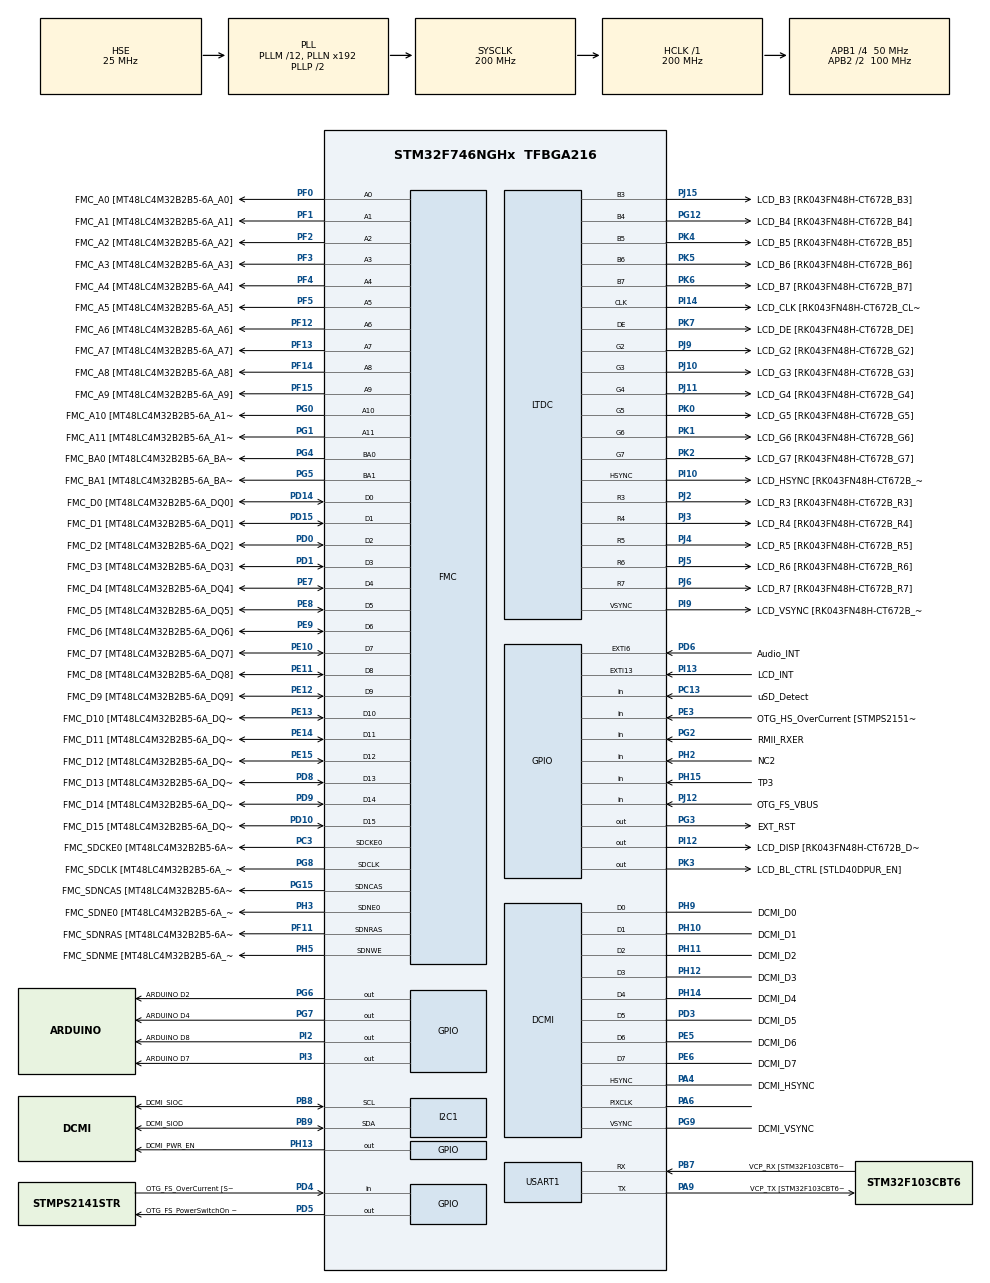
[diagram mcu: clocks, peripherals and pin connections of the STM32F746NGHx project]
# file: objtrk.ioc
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PD12.GPIO_Label=QSPI_D1 [N25Q128A13EF840E_DQ1]
FMC.SDClockPeriod2=FMC_SDRAM_CLOCK_PERIOD_2
FMC.SDClockPeriod1=FMC_SDRAM_CLOCK_PERIOD_2
SH.FMC_A0.0=FMC_A0,12b-sda1
PH15.GPIO_Label=TP3
PG8.Signal=FMC_SDCLK
PG0.Signal=FMC_A10
PI15.GPIO_Label=LCD_R0 [RK043FN48H-CT672B_R0]
PK1.Signal=LTDC_G6
SH.FMC_D5_DA5.0=FMC_D5,sd-16b-d1
PF10.GPIO_PuPd=GPIO_NOPULL
SH.FMC_D9_DA9.0=FMC_D9,sd-16b-d1
PG15.GPIO_Label=FMC_SDNCAS [MT48LC4M32B2B5-6A_CAS]
PA4.Mode=Slave_8_bits_External_Synchro
PF7.Signal=ADC3_IN5
SH.FMC_SDNWE.0=FMC_SDNWE,12b-sda1
PH9.Signal=DCMI_D0
SH.FMC_D11_DA11.0=FMC_D11,sd-16b-d1
PJ5.Mode=RGB565
RCC.APB2TimFreq_Value=200000000
PB6.Signal=QUADSPI_BK1_NCS
PC7.Signal=USART6_RX
PD0.Signal=FMC_D2_DA2
PD8.Signal=FMC_D13_DA13
PE1.Signal=FMC_NBL1
PF1.GPIO_Label=FMC_A1 [MT48LC4M32B2B5-6A_A1]
PI4.GPIO_Label=SAI2_MCLKA [WM8994ECS/R_MCLK1]
PK4.GPIO_Label=LCD_B5 [RK043FN48H-CT672B_B5]
PD1.GPIO_Label=FMC_D3 [MT48LC4M32B2B5-6A_DQ3]
DCMI.PCKPolarity=DCMI_PCKPOLARITY_RISING
PB12.GPIO_Label=ULPI_D5 [USB3320C-EZK_D5]
FMC.SelfRefreshTime1=4
PF12.GPIO_Label=FMC_A6 [MT48LC4M32B2B5-6A_A6]
LTDC.PixelFormat_L0=LTDC_PIXEL_FORMAT_RGB565
SH.S_TIM12_CH1.0=TIM12_CH1
PC4.GPIO_Label=RMII_RXD0 [LAN8742A-CZ-TR_RXD0]
PE9.Signal=FMC_D6_DA6
SH.FMC_A2.0=FMC_A2,12b-sda1
PB1.GPIO_Label=ULPI_D2 [USB3320C-EZK_D2]
PE4.GPIO_Label=LCD_B0 [RK043FN48H-CT672B_B0]
PG4.GPIO_Label=FMC_BA0 [MT48LC4M32B2B5-6A_BA0]
PA8.Signal=S_TIM1_CH1
SH.FMC_D1_DA1.0=FMC_D1,sd-16b-d1
LTDC.HSync=41
PJ14.Signal=LTDC_B2
PB9.Signal=I2C1_SDA
Mcu.Package=TFBGA216
PB1.Signal=USB_OTG_HS_ULPI_D2
PB14.GPIO_PuPd=GPIO_NOPULL
PH12.Mode=Slave_8_bits_External_Synchro
PD12.Signal=QUADSPI_BK1_IO1
PH11.Mode=Slave_8_bits_External_Synchro
PB9.GPIO_PuPd=GPIO_NOPULL
PA10.Signal=USB_OTG_FS_ID
PE12.GPIO_Label=FMC_D9 [MT48LC4M32B2B5-6A_DQ9]
FMC.WriteRecoveryTime1=3
RCC.APB2CLKDivider=RCC_HCLK_DIV2
LTDC.VSync=10
RCC.APB1TimFreq_Value=100000000
PC14/OSC32_IN.GPIO_Label=RCC_OSC32_IN
FMC.RowCycleDelay2=7
FMC.RowCycleDelay1=7
PF9.GPIO_PuPd=GPIO_NOPULL
PA4.GPIO_Label=DCMI_HSYNC
PA8.GPIO_Speed=GPIO_SPEED_FREQ_LOW
PD15.Signal=FMC_D1_DA1
PJ1.GPIO_Label=LCD_R2 [RK043FN48H-CT672B_R2]
PG12.Signal=LTDC_B4
SH.FMC_A4.0=FMC_A4,12b-sda1
PK4.Signal=LTDC_B5
PH13.Signal=GPIO_Output
PI13.GPIO_ModeDefaultEXTI=GPIO_MODE_EVT_RISING
PG5.Signal=FMC_A15_BA1
PC13.Signal=GPIO_Input
SH.FMC_D10_DA10.0=FMC_D10,sd-16b-d1
PD3.Signal=DCMI_D5
PI10.Mode=RGB565
PG9.Mode=Slave_8_bits_External_Synchro
PC2.Signal=USB_OTG_HS_ULPI_DIR
PI12.Signal=GPIO_Output
PJ11.Signal=LTDC_G4
PF8.GPIO_Label=ARDUINO A3
LTDC.ImageWidth_L0=480
PD10.Signal=FMC_D15_DA15
PJ6.Mode=RGB565
PB8.GPIO_Label=DCMI_SIOC
PJ8.GPIO_Label=LCD_G1 [RK043FN48H-CT672B_G1]
PJ3.Signal=LTDC_R4
PI8.GPIO_Label=NC1 [TP2]
PA8.GPIO_Label=ARDUINO PWM/D10
PE8.GPIO_Label=FMC_D5 [MT48LC4M32B2B5-6A_DQ5]
PH9.Mode=Slave_8_bits_External_Synchro
PH11.GPIO_Label=DCMI_D2
PJ11.GPIO_Label=LCD_G4 [RK043FN48H-CT672B_G4]
PB14.Signal=SPI2_MISO
PA5.Signal=USB_OTG_HS_ULPI_CK
PF10.GPIO_Mode=GPIO_MODE_ANALOG
PJ4.GPIO_Label=LCD_R5 [RK043FN48H-CT672B_R5]
PE1.GPIO_Label=FMC_NBL1 [MT48LC4M32B2B5-6A_DQM1]
PK7.GPIO_Label=LCD_DE [RK043FN48H-CT672B_DE]
PI7.Signal=SAI2_FS_A
FMC.ReadBurst1=FMC_SDRAM_RBURST_ENABLE
SH.FMC_A6.0=FMC_A6,12b-sda1
FMC.ReadBurst2=FMC_SDRAM_RBURST_ENABLE
PE14.Signal=FMC_D11_DA11
PE6.Mode=Slave_8_bits_External_Synchro
PB4.GPIO_Label=ARDUINO PWM/D3
PB15.GPIO_Label=ARDUINO MOSI/PWM/D11
PG7.GPIO_Label=ARDUINO D4
PI2.Signal=GPIO_Output
PF4.GPIO_Label=FMC_A4 [MT48LC4M32B2B5-6A_A4]
PA1.GPIO_Label=RMII_REF_CLK [LAN8742A-CZ-TR_REFCLK0]
PF13.Signal=FMC_A7
PA0/WKUP.GPIO_PuPd=GPIO_NOPULL
PJ15.GPIO_Label=LCD_B3 [RK043FN48H-CT672B_B3]
PC7.GPIO_Label=ARDUINO RX/D0
PJ15.Mode=RGB565
PA5.GPIO_Label=ULPI_CLK [USB3320C-EZK_CLKOUT]
PK4.Mode=RGB565
PC12.GPIO_Label=SDMMC_CK
PE5.GPIO_Label=DCMI_D6
PJ8.Signal=LTDC_G1
PJ0.GPIO_Label=LCD_R1 [RK043FN48H-CT672B_R1]
ProjectManager.HeapSize=0x200
PH6.Signal=S_TIM12_CH1
NVIC.PriorityGroup=NVIC_PRIORITYGROUP_4
PF0.GPIO_Label=FMC_A0 [MT48LC4M32B2B5-6A_A0]
PI1.GPIO_Mode=GPIO_MODE_AF_PP
PE3.Signal=GPIO_Input
PJ4.Mode=RGB565
PC15/OSC32_OUT.Signal=RCC_OSC32_OUT
Dma.DCMI.0.PeriphInc=DMA_PINC_DISABLE
PF4.Signal=FMC_A4
PD2.Signal=SDMMC1_CMD
PI1.GPIO_Label=ARDUINO SCK/D13
Mcu.Family=STM32F7
LTDC.BlendingFactor1_L0=LTDC_BLENDING_FACTOR1_PAxCA
PA6.Mode=Slave_8_bits_External_Synchro
PK3.Signal=GPIO_Output
SH.FMC_A8.0=FMC_A8,12b-sda1
PC15/OSC32_OUT.GPIO_Label=RCC_OSC32_OUT
PH14.Signal=DCMI_D4
PH10.Signal=DCMI_D1
SH.FMC_D14_DA14.0=FMC_D14,sd-16b-d1
PG2.Signal=GPIO_Input
PE11.GPIO_Label=FMC_D8 [MT48LC4M32B2B5-6A_DQ8]
PD0.GPIO_Label=FMC_D2 [MT48LC4M32B2B5-6A_DQ2]
PC14/OSC32_IN.Mode=LSE-External-Oscillator
SH.FMC_A14_BA0.0=FMC_BA0,FourSdramBanks1
SH.FMC_A11.0=FMC_A11,12b-sda1
PB13.GPIO_Label=ULPI_D6 [USB3320C-EZK_D6]
PG5.GPIO_Label=FMC_BA1 [MT48LC4M32B2B5-6A_BA1]
PB15.Signal=SPI2_MOSI
PG15.Signal=FMC_SDNCAS
PG11.Signal=ETH_TX_EN
PJ5.GPIO_Label=LCD_R6 [RK043FN48H-CT672B_R6]
PJ14.GPIO_Label=LCD_B2 [RK043FN48H-CT672B_B2]
Dma.DCMI.0.FIFOMode=DMA_FIFOMODE_ENABLE
PD13.Signal=QUADSPI_BK1_IO3
Dma.DCMI.0.FIFOThreshold=DMA_FIFO_THRESHOLD_FULL
PA15.GPIO_Label=ARDUINO PWM/D9
Dma.DCMI.0.MemInc=DMA_MINC_ENABLE
PJ2.Signal=LTDC_R3
PH10.Mode=Slave_8_bits_External_Synchro
SH.FMC_NBL1.0=FMC_NBL1
LTDC.WindowX1_L0=480
PI9.Mode=RGB565
PK2.Mode=RGB565
PA15.GPIO_ModeDefaultPP=GPIO_MODE_AF_PP
PA9.GPIO_Mode=GPIO_MODE_AF_PP
RCC.HSE_VALUE=25000000
FMC.ExitSelfRefreshDelay1=7
PF7.GPIO_Mode=GPIO_MODE_ANALOG
PI14.Mode=RGB565
PF8.GPIO_PuPd=GPIO_NOPULL
PH7.GPIO_Label=LCD_SCL [RK043FN48H-CT672B_SCL]
PJ7.GPIO_Label=LCD_G0 [RK043FN48H-CT672B_G0]
PF11.Signal=FMC_SDNRAS
PC11.GPIO_Label=SDMMC_D3
PJ12.GPIO_Label=OTG_FS_VBUS
PB7.Signal=USART1_RX
Dma.DCMI.0.PeriphBurst=DMA_PBURST_SINGLE
SH.S_TIM3_CH1.0=TIM3_CH1
PB7.GPIO_Label=VCP_RX [STM32F103CBT6_PA2]
PD13.GPIO_Label=QSPI_D3 [N25Q128A13EF840E_DQ3]
PA6.Signal=DCMI_PIXCLK
Dma.DCMI.0.Direction=DMA_PERIPH_TO_MEMORY
PB15.GPIO_PuPd=GPIO_NOPULL
PD5.GPIO_Label=OTG_FS_PowerSwitchOn [STMPS2141STR_EN]
PA15.Signal=S_TIM2_CH1_ETR
PF8.Signal=ADC3_IN6
PG0.GPIO_Label=FMC_A10 [MT48LC4M32B2B5-6A_A10]
PI0.GPIO_Label=ARDUINO PWM/CS/D5
PA0/WKUP.GPIO_Mode=GPIO_MODE_ANALOG
PB5.GPIO_Label=ULPI_D7 [USB3320C-EZK_D7]
PG11.GPIO_Label=RMII_TX_EN [LAN8742A-CZ-TR_TXEN]
PD3.GPIO_Label=DCMI_D5
PC5.Signal=ETH_RXD1
PE7.Signal=FMC_D4_DA4
PD6.Signal=GPXTI6
Dma.Request0=DCMI
PF3.GPIO_Label=FMC_A3 [MT48LC4M32B2B5-6A_A3]
PE2.GPIO_Label=QSPI_D2 [N25Q128A13EF840E_DQ2]
PB4.Signal=S_TIM3_CH1
PG2.GPIO_Label=RMII_RXER
PA3.Signal=USB_OTG_HS_ULPI_D0
PK1.Mode=RGB565
PK6.Signal=LTDC_B7
NVIC.LTDC_IRQn=true\:0\:0\:false\:false\:true\:true\:true
PD15.GPIO_Label=FMC_D1 [MT48LC4M32B2B5-6A_DQ1]
LTDC.WindowY1_L0=272
PG7.Signal=GPIO_Output
PH12.GPIO_Label=DCMI_D3
PC11.Signal=SDMMC1_D3
PI14.Signal=LTDC_CLK
PC8.Signal=SDMMC1_D0
PE14.GPIO_Label=FMC_D11 [MT48LC4M32B2B5-6A_DQ11]
PD9.Signal=FMC_D14_DA14
PA9.GPIO_PuPd=GPIO_NOPULL
PA12.GPIO_Label=OTG_FS_P
PD8.GPIO_Label=FMC_D13 [MT48LC4M32B2B5-6A_DQ13]
PG8.GPIO_Label=FMC_SDCLK [MT48LC4M32B2B5-6A_CLK]
USART1.VirtualMode-Asynchronous=VM_ASYNC
PA13.Signal=SYS_JTMS-SWDIO
PA9.Mode=Asynchronous
SH.S_TIM1_CH1.0=TIM1_CH1
PF6.Signal=ADC3_IN4
PB10.GPIO_Label=ULPI_D3 [USB3320C-EZK_D3]
SH.FMC_D13_DA13.0=FMC_D13,sd-16b-d1
PH8.Signal=I2C3_SDA
PB9.Mode=I2C
Dma.DCMI.0.Instance=DMA2_Stream1
Dma.DCMI.0.Mode=DMA_CIRCULAR
RCC.USBFreq_Value=200000000
PF9.GPIO_Label=ARDUINO A2
PD10.GPIO_Label=FMC_D15 [MT48LC4M32B2B5-6A_DQ15]
PA1.Signal=ETH_REF_CLK
PK5.Mode=RGB565
board=STM32F746G-DISCO
PG12.Mode=RGB565
RCC.VCOOutputFreq_Value=400000000
PI9.Signal=LTDC_VSYNC
PH4.GPIO_Label=ULPI_NXT [USB3320C-EZK_NXT]
PI13.GPIO_Label=LCD_INT
PI4.Signal=SAI2_MCLK_A
PE5.Mode=Slave_8_bits_External_Synchro
PC1.GPIO_Label=RMII_MDC [LAN8742A-CZ-TR_MDC]
SH.FMC_D12_DA12.0=FMC_D12,sd-16b-d1
PF15.GPIO_Label=FMC_A9 [MT48LC4M32B2B5-6A_A9]
PI1.GPIO_Speed=GPIO_SPEED_FREQ_LOW
PF1.Signal=FMC_A1
PF8.GPIO_Mode=GPIO_MODE_ANALOG
PJ0.Signal=LTDC_R1
PE0.Signal=FMC_NBL0
PE7.GPIO_Label=FMC_D4 [MT48LC4M32B2B5-6A_DQ4]
PE12.Signal=FMC_D9_DA9
RCC.SYSCLKFreq_VALUE=200000000
PJ5.Signal=LTDC_R6
PA15.GPIO_Speed=GPIO_SPEED_FREQ_LOW
RCC.HSI_VALUE=16000000
PA8.GPIO_PuPd=GPIO_NOPULL
PH0/OSC_IN.GPIO_Label=OSC_25M [NZ2520SB-25.00M_OUT]
PF9.GPIO_Mode=GPIO_MODE_ANALOG
PI3.GPIO_Label=ARDUINO D7
PH3.Signal=FMC_SDNE0
RCC.PLLM=12
PA9.GPIO_Speed=GPIO_SPEED_FREQ_LOW
PB8.GPIO_Speed=GPIO_SPEED_FREQ_LOW
PJ2.GPIO_Label=LCD_R3 [RK043FN48H-CT672B_R3]
LTDC.ImageHeight_L0=272
PB14.GPIO_Mode=GPIO_MODE_AF_PP
PB12.Signal=USB_OTG_HS_ULPI_D5
PJ13.Signal=LTDC_B1
PK1.GPIO_Label=LCD_G6 [RK043FN48H-CT672B_G6]
PA3.GPIO_Label=ULPI_D0 [USB3320C-EZK_D0]
PI12.PinState=GPIO_PIN_SET
SH.FMC_D7_DA7.0=FMC_D7,sd-16b-d1
PK5.Signal=LTDC_B6
PB15.GPIO_Mode=GPIO_MODE_AF_PP
PJ9.Mode=RGB565
PH12.Signal=DCMI_D3
FMC.RCDDelay1=2
PK0.Mode=RGB565
PG4.Signal=FMC_A14_BA0
PC12.Signal=SDMMC1_CK
PB14.GPIO_Label=ARDUINO MISO/D12
PA14.GPIO_Label=SWCLK
PG6.GPIO_Label=ARDUINO D2
PH6.GPIO_Label=ARDUINO PWM/D6
FMC.LoadToActiveDelay1=2
PK6.GPIO_Label=LCD_B7 [RK043FN48H-CT672B_B7]
PC6.GPIO_Label=ARDUINO TX/D1
PI6.GPIO_Label=SAI2_SDA [WM8994ECS/R_DACDAT1]
PB6.GPIO_Label=QSPI_NCS [N25Q128A13EF840E_S]
PJ6.GPIO_Label=LCD_R7 [RK043FN48H-CT672B_R7]
Dma.DCMI.0.MemBurst=DMA_MBURST_SINGLE
PB13.Signal=USB_OTG_HS_ULPI_D6
PD6.GPIO_Label=Audio_INT
PG13.Signal=ETH_TXD0
PE6.GPIO_Label=DCMI_D7
PF6.GPIO_Label=ARDUINO A5
RCC.SYSCLKSource=RCC_SYSCLKSOURCE_PLLCLK
PJ10.Signal=LTDC_G3
SH.FMC_A15_BA1.0=FMC_BA1,FourSdramBanks1
Dma.DCMI.0.MemDataAlignment=DMA_MDATAALIGN_WORD
PB7.GPIO_Mode=GPIO_MODE_AF_PP
PJ13.GPIO_Label=LCD_B1 [RK043FN48H-CT672B_B1]
PI0.GPIO_PuPd=GPIO_NOPULL
PH5.Signal=FMC_SDNWE
Dma.DCMI.0.PeriphDataAlignment=DMA_PDATAALIGN_WORD
PD4.Signal=GPIO_Input
PH1/OSC_OUT.Signal=RCC_OSC_OUT
PC3.Signal=FMC_SDCKE0
PE5.Signal=DCMI_D6
PF10.GPIO_Label=ARDUINO A1
PH10.GPIO_Label=DCMI_D1
PB2.Signal=QUADSPI_CLK
PK7.Mode=RGB565
PJ2.Mode=RGB565
PI6.Signal=SAI2_SD_A
PI3.Signal=GPIO_Output
PE2.Signal=QUADSPI_BK1_IO2
PF3.Signal=FMC_A3
PD3.Mode=Slave_8_bits_External_Synchro
PE10.Signal=FMC_D7_DA7
PD6.GPIO_ModeDefaultEXTI=GPIO_MODE_EVT_RISING
PJ4.Signal=LTDC_R5
SH.FMC_A1.0=FMC_A1,12b-sda1
PH2.Signal=GPIO_Input
SH.FMC_SDCLK.0=FMC_SDCLK,12b-sda1
PF14.Signal=FMC_A8
VP_DMA2D_VS_DMA2D.Mode=DMA2D_Activate
PF6.GPIO_Mode=GPIO_MODE_ANALOG
PE10.GPIO_Label=FMC_D7 [MT48LC4M32B2B5-6A_DQ7]
SH.FMC_D3_DA3.0=FMC_D3,sd-16b-d1
PI10.GPIO_Label=LCD_HSYNC [RK043FN48H-CT672B_HSYNC]
PB7.GPIO_PuPd=GPIO_NOPULL
PK3.PinState=GPIO_PIN_SET
PH15.Signal=GPIO_Input
PD9.GPIO_Label=FMC_D14 [MT48LC4M32B2B5-6A_DQ14]
PG9.Signal=DCMI_VSYNC
PA9.GPIO_Label=VCP_TX [STM32F103CBT6_PA3]
PB8.GPIO_PuPd=GPIO_NOPULL
PC6.Signal=USART6_TX
PB11.GPIO_Label=ULPI_D4 [USB3320C-EZK_D4]
PD7.Signal=SPDIFRX_IN0
PD1.Signal=FMC_D3_DA3
PA11.GPIO_Label=OTG_FS_N
PF14.GPIO_Label=FMC_A8 [MT48LC4M32B2B5-6A_A8]
NVIC.DMA2_Stream1_IRQn=true\:0\:0\:false\:false\:true\:false\:true
PC0.Signal=USB_OTG_HS_ULPI_STP
RCC.APB1CLKDivider=RCC_HCLK_DIV4
PF13.GPIO_Label=FMC_A7 [MT48LC4M32B2B5-6A_A7]
PG13.GPIO_Label=RMII_TXD0 [LAN8742A-CZ-TR_TXD0]
PG10.Signal=SAI2_SD_B
SH.FMC_A3.0=FMC_A3,12b-sda1
PJ7.Signal=LTDC_G0
FMC.CASLatency1=FMC_SDRAM_CAS_LATENCY_2
PI0.GPIO_Speed=GPIO_SPEED_FREQ_LOW
PB14.GPIO_Speed=GPIO_SPEED_FREQ_LOW
SH.FMC_D15_DA15.0=FMC_D15,sd-16b-d1
PA9.Signal=USART1_TX
I2C1.Timing=0x00C0EAFF
PB4.GPIO_PuPd=GPIO_NOPULL
PE9.GPIO_Label=FMC_D6 [MT48LC4M32B2B5-6A_DQ6]
PB10.Signal=USB_OTG_HS_ULPI_D3
PJ15.Signal=LTDC_B3
PH9.GPIO_Label=DCMI_D0
PI9.GPIO_Label=LCD_VSYNC [RK043FN48H-CT672B_VSYNC]
PA8.GPIO_ModeDefaultPP=GPIO_MODE_AF_PP
PH14.Mode=Slave_8_bits_External_Synchro
PE15.Signal=FMC_D12_DA12
PE8.Signal=FMC_D5_DA5
PI1.Signal=SPI2_SCK
PA0/WKUP.GPIO_Label=ARDUINO A0
PG14.GPIO_Label=RMII_TXD1 [LAN8742A-CZ-TR_TXD1]
SH.FMC_SDNCAS.0=FMC_SDNCAS,12b-sda1
PF7.GPIO_PuPd=GPIO_NOPULL
PH14.GPIO_Label=DCMI_D4
PA4.Signal=DCMI_HSYNC
PB5.Signal=USB_OTG_HS_ULPI_D7
PE13.GPIO_Label=FMC_D10 [MT48LC4M32B2B5-6A_DQ10]
PD11.Signal=QUADSPI_BK1_IO0
SH.FMC_A5.0=FMC_A5,12b-sda1
LTDC.Alpha_L0=255
PA11.Signal=USB_OTG_FS_DM
SH.S_TIM2_CH1_ETR.0=TIM2_CH1
PK3.GPIO_Label=LCD_BL_CTRL [STLD40DPUR_EN]
PF9.Signal=ADC3_IN7
PJ10.Mode=RGB565
PB8.Mode=I2C
PF6.GPIO_PuPd=GPIO_NOPULL
PC3.GPIO_Label=FMC_SDCKE0 [MT48LC4M32B2B5-6A_CKE]
PG3.GPIO_Label=EXT_RST
PB0.Signal=USB_OTG_HS_ULPI_D1
PC1.Signal=ETH_MDC
PG10.GPIO_Label=SAI2_SDB [WM8994ECS/R_ADCDAT1]
PD2.GPIO_Label=SDMMC_D0
PH2.GPIO_Label=NC2
Dma.DCMI.0.Priority=DMA_PRIORITY_VERY_HIGH
PC3.Mode=SdramChipSelect1_1
PK7.Signal=LTDC_DE
RCC.CortexFreq_Value=200000000
PG6.Signal=GPIO_Output
LTDC.HBP=13
PC10.Signal=SDMMC1_D2
SH.FMC_NBL0.0=FMC_NBL0
PC0.GPIO_Label=ULPI_STP [USB3320C-EZK_STP]
SH.FMC_D6_DA6.0=FMC_D6,sd-16b-d1
PA0/WKUP.Signal=ADCx_IN0
PB0.GPIO_Label=ULPI_D1 [USB3320C-EZK_D1]
PH5.GPIO_Label=FMC_SDNME [MT48LC4M32B2B5-6A_WE]
PI5.GPIO_Label=SAI2_SCKA [WM8994ECS/R_BCLK1]
PC13.GPIO_Label=uSD_Detect
PK5.GPIO_Label=LCD_B6 [RK043FN48H-CT672B_B6]
PB11.Signal=USB_OTG_HS_ULPI_D4
PI14.GPIO_Label=LCD_CLK [RK043FN48H-CT672B_CLK]
ProjectManager.StackSize=0x400
PH3.Mode=SdramChipSelect1_1
PJ6.Signal=LTDC_R7
SH.FMC_A7.0=FMC_A7,12b-sda1
PA12.Signal=USB_OTG_FS_DP
PH0/OSC_IN.Mode=HSE-External-Oscillator
PD11.GPIO_Label=QSPI_D0 [N25Q128A13EF840E_DQ0]
RCC.HCLKFreq_Value=200000000
DCMI.VSPolarity=DCMI_VSPOLARITY_HIGH
PF11.GPIO_Label=FMC_SDNRAS [MT48LC4M32B2B5-6A_RAS]
PF12.Signal=FMC_A6
PI13.Signal=GPXTI13
SH.FMC_A10.0=FMC_A10,12b-sda1
RCC.AHBFreq_Value=200000000
SH.FMC_D8_DA8.0=FMC_D8,sd-16b-d1
FMC.RPDelay2=2
FMC.RPDelay1=2
PI8.Signal=RTC_TS
SH.FMC_D2_DA2.0=FMC_D2,sd-16b-d1
PE13.Signal=FMC_D10_DA10
PF7.GPIO_Label=ARDUINO A4
PI1.GPIO_PuPd=GPIO_NOPULL
PI5.Signal=SAI2_SCK_A
PK6.Mode=RGB565
PI0.Signal=S_TIM5_CH4
PA10.GPIO_Label=OTG_FS_ID
LTDC.HFP=32
LTDC.BlendingFactor2_L0=LTDC_BLENDING_FACTOR2_PAxCA
SH.ADCx_IN0.0=ADC3_IN0
SH.FMC_SDNRAS.0=FMC_SDNRAS,12b-sda1
DMA2D.ColorMode=DMA2D_OUTPUT_RGB565
LTDC.ActiveW=480
PE4.Signal=LTDC_B0
PH1/OSC_OUT.Mode=HSE-External-Oscillator
PD7.GPIO_Label=SPDIF_RX0 [74LVC1G04SE_4]
PJ9.Signal=LTDC_G2
SH.FMC_D0_DA0.0=FMC_D0,sd-16b-d1
PJ12.Signal=GPIO_Input
PC14/OSC32_IN.Signal=RCC_OSC32_IN
PK0.GPIO_Label=LCD_G5 [RK043FN48H-CT672B_G5]
PA2.GPIO_Label=RMII_MDIO [LAN8742A-CZ-TR_MDIO]
PF5.GPIO_Label=FMC_A5 [MT48LC4M32B2B5-6A_A5]
SH.FMC_A9.0=FMC_A9,12b-sda1
PJ1.Signal=LTDC_R2
SH.FMC_D4_DA4.0=FMC_D4,sd-16b-d1
PI12.GPIO_Label=LCD_DISP [RK043FN48H-CT672B_DISP] 
PE0.GPIO_Label=FMC_NBL0 [MT48LC4M32B2B5-6A_DQM0]
RCC.PLLSAIN=50
PH3.GPIO_Label=FMC_SDNE0 [MT48LC4M32B2B5-6A_CS]
PF5.Signal=FMC_A5
PH7.Signal=I2C3_SCL
PB9.GPIO_Speed=GPIO_SPEED_FREQ_LOW
PJ3.GPIO_Label=LCD_R4 [RK043FN48H-CT672B_R4]
PK2.GPIO_Label=LCD_G7 [RK043FN48H-CT672B_G7]
PF0.Signal=FMC_A0
PI2.GPIO_Label=ARDUINO D8
PC2.GPIO_Label=ULPI_DIR [USB3320C-EZK_DIR]
PB7.GPIO_Speed=GPIO_SPEED_FREQ_LOW
PB3.GPIO_Label=SWO
RCC.PLLSourceVirtual=RCC_PLLSOURCE_HSE
PK2.Signal=LTDC_G7
LTDC.FBStartAdress_L0=0xC0000000
PB9.GPIO_Label=DCMI_SIOD
PC10.GPIO_Label=SDMMC_D2
PH11.Signal=DCMI_D2
PG3.Signal=GPIO_Output
PG1.Signal=FMC_A11
PC4.Signal=ETH_RXD0
PI0.GPIO_ModeDefaultPP=GPIO_MODE_AF_PP
PI10.Signal=LTDC_HSYNC
PD5.Signal=GPIO_Output
PJ11.Mode=RGB565
PH13.GPIO_Label=DCMI_PWR_EN
PH8.GPIO_Label=LCD_SDA [RK043FN48H-CT672B_SDA]
PE15.GPIO_Label=FMC_D12 [MT48LC4M32B2B5-6A_DQ12]
PH4.Signal=USB_OTG_HS_ULPI_NXT
ProjectManager.TargetToolchain=STM32CubeIDE
LTDC.ActiveH=272
PJ9.GPIO_Label=LCD_G2 [RK043FN48H-CT672B_G2]
PF2.Signal=FMC_A2
PE11.Signal=FMC_D8_DA8
PK0.Signal=LTDC_G5
PG9.GPIO_Label=DCMI_VSYNC
PG14.Signal=ETH_TXD1
PB4.GPIO_ModeDefaultPP=GPIO_MODE_AF_PP
PJ10.GPIO_Label=LCD_G3 [RK043FN48H-CT672B_G3]
PG1.GPIO_Label=FMC_A11 [MT48LC4M32B2B5-6A_A11]
PB9.GPIO_Mode=GPIO_MODE_AF_OD
PJ3.Mode=RGB565
PH0/OSC_IN.Signal=RCC_OSC_IN
PB4.GPIO_Speed=GPIO_SPEED_FREQ_LOW
RCC.APB2Freq_Value=100000000
LTDC.Layers=0
PD4.GPIO_Label=OTG_FS_OverCurrent [STMPS2141STR_Fault]
PF10.Signal=ADC3_IN8
PB15.GPIO_Speed=GPIO_SPEED_FREQ_LOW
PI7.GPIO_Label=SAI2_FSA [WM8994ECS/R_LRCLK1]
SH.S_TIM5_CH4.0=TIM5_CH4
PF15.Signal=FMC_A9
PD14.GPIO_Label=FMC_D0 [MT48LC4M32B2B5-6A_DQ0]
PD5.PinState=GPIO_PIN_SET
PE6.Signal=DCMI_D7
Mcu.Name=STM32F746NGHx
PA13.GPIO_Label=SWDIO
PA2.Signal=ETH_MDIO
PD14.Signal=FMC_D0_DA0
PB3.Signal=SYS_JTDO-SWO
PA7.GPIO_Label=RMII_CRS_DV [LAN8742A-CZ-TR_CRS_DV]
PC5.GPIO_Label=RMII_RXD1 [LAN8742A-CZ-TR_RXD1]
PC15/OSC32_OUT.Mode=LSE-External-Oscillator
PB7.Mode=Asynchronous
PA14.Signal=SYS_JTCK-SWCLK
PG12.GPIO_Label=LCD_B4 [RK043FN48H-CT672B_B4]
PA15.GPIO_PuPd=GPIO_NOPULL
PI15.Signal=LTDC_R0
PB8.Signal=I2C1_SCL
PE3.GPIO_Label=OTG_HS_OverCurrent [STMPS2151STR_FAULT]
PC9.Signal=SDMMC1_D1
NVIC.DCMI_IRQn=true\:0\:0\:false\:false\:true\:true\:true
PB8.GPIO_Mode=GPIO_MODE_AF_OD
RCC.APB1Freq_Value=50000000
DMA2D.Mode=DMA2D_M2M
PA7.Signal=ETH_CRS_DV
PF2.GPIO_Label=FMC_A2 [MT48LC4M32B2B5-6A_A2]

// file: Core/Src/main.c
/* USER CODE BEGIN Header */
/**
  ******************************************************************************
  * @file           : main.c
  * @brief          : Main program body
  ******************************************************************************
  * @attention
  *
  * <h2><center>&copy; Copyright (c) 2021 STMicroelectronics.
  * All rights reserved.</center></h2>
  *
  * This software component is licensed by ST under BSD 3-Clause license,
  * the "License"; You may not use this file except in compliance with the
  * License. You may obtain a copy of the License at:
  *                        opensource.org/licenses/BSD-3-Clause
  *
  ******************************************************************************
  */
/* USER CODE END Header */
#include "main.h"

DCMI_HandleTypeDef hdcmi;
DMA_HandleTypeDef hdma_dcmi;

DMA2D_HandleTypeDef hdma2d;

I2C_HandleTypeDef hi2c1;

LTDC_HandleTypeDef hltdc;

UART_HandleTypeDef huart1;

SDRAM_HandleTypeDef hsdram1;

void SystemClock_Config(void);
static void MX_GPIO_Init(void);
static void MX_DMA_Init(void);
static void MX_USART1_UART_Init(void);
static void MX_FMC_Init(void);
static void MX_LTDC_Init(void);
static void MX_DMA2D_Init(void);
static void MX_DCMI_Init(void);
static void MX_I2C1_Init(void);

/* USER CODE BEGIN 0 */
int __io_putchar(int ch) {
	if ( HAL_UART_Transmit(&huart1, (uint8_t*)&ch, 1, 1000) == HAL_OK )
		return ch;
	else
		return 0;
}

int dma2d_fps = 0;
int dcmi_fps = 0;

#define SCREEN_W (480)
#define SCREEN_H (272)
#define VRAM_SIZE (2 * SCREEN_W * SCREEN_H)

#define CAPTURE_W (240)
#define CAPTURE_H (240)
#define CAPTURE_SIZE (2 * CAPTURE_W * CAPTURE_H)

uint16_t buf[CAPTURE_W * CAPTURE_H];
#define CAPTURE_MEM ((uint32_t)((uint16_t *)buf))
#define CAPTURE_MEM0 (SDRAM_BANK_ADDR + VRAM_SIZE)
#define CAPTURE_MEM1 (SDRAM_BANK_ADDR + VRAM_SIZE + 2 * CAPTURE_SIZE)

bool dcmi_sw = false;
uint32_t buffaddr[2] = { CAPTURE_MEM0, CAPTURE_MEM1 };

void HAL_DCMI_FrameEventCallback(DCMI_HandleTypeDef *hdcmi) {

	dcmi_fps++;

	HAL_DCMI_Stop(hdcmi);

	HAL_DMA2D_Start_IT(
			&hdma2d,
			buffaddr[dcmi_sw],
			SDRAM_BANK_ADDR + ((SCREEN_W - CAPTURE_W) / 2 + ((SCREEN_H - CAPTURE_H) /  2) * SCREEN_W) * 2,
			CAPTURE_W,
			CAPTURE_H
	);

	dcmi_sw = !dcmi_sw;

	HAL_DCMI_Start_DMA(hdcmi, DCMI_MODE_SNAPSHOT, buffaddr[dcmi_sw], CAPTURE_SIZE / 4);

}

void DMA2D_XferCpltCallback(DMA2D_HandleTypeDef *hdma2d) {

	dma2d_fps++;

}

void DMA2D_XferErrorCallback(DMA2D_HandleTypeDef *hdma2d) {

	printf("DMA2D XferError\r\n");

}
/* USER CODE END 0 */

int main(void)
{

  /* MCU Configuration--------------------------------------------------------*/

  /* Reset of all peripherals, Initializes the Flash interface and the Systick. */
  HAL_Init();

  /* Configure the system clock */
  SystemClock_Config();

  /* Initialize all configured peripherals */
  MX_GPIO_Init();
  MX_DMA_Init();
  MX_USART1_UART_Init();
  MX_FMC_Init();
  MX_LTDC_Init();
  MX_DMA2D_Init();
  MX_DCMI_Init();
  MX_I2C1_Init();
  /* USER CODE BEGIN 2 */

  SDRAM_Initialization_sequence();
  printf("SDRAM INIT SEQ DONE\r\n");

  CAMERA_Initialization_sequence();
  printf("CAMERA INIT SEQ DONE\r\n");

  hdma2d.Init.Mode = DMA2D_R2M;
  HAL_DMA2D_Init(&hdma2d);
  HAL_DMA2D_Start(&hdma2d, 0, 0xC0000000, SCREEN_W, SCREEN_H);
  HAL_DMA2D_PollForTransfer(&hdma2d, 10);

  hdma2d.Init.Mode = DMA2D_M2M;
  hdma2d.Init.OutputOffset = SCREEN_W - CAPTURE_W; // number of pixels on each line that should be ignored
  hdma2d.XferCpltCallback = DMA2D_XferCpltCallback;
  HAL_DMA2D_Init(&hdma2d);

  /* For 240x240 resolution, the OV9655 sensor is set to QVGA resolution
   * as OV9655 doesn't supports 240x240  resolution,
   * then DCMI is configured to output a 240x240 cropped window
   *
   * CWSIZER; DCMI crop window size,
   * CWSTRTR; DCMI crop window start,
   *
   * hdcmi->Instance->CWSIZER = (XSize | (YSize << DCMI_CWSIZE_VLINE_Pos));
   * hdcmi->Instance->CWSTRTR = (X0 | (Y0 << DCMI_CWSTRT_VST_Pos));
   */
  HAL_DCMI_ConfigCrop(
		  &hdcmi,
		  40,            /* X0 DCMI window X offset   : Crop in the middle of the VGA picture */
		  0,             /* Y0 DCMI window Y offset   : Same height (same number of lines: no need to crop vertically) */
		  (240 * 2) - 1, /* XSIZE DCMI Pixel per line : 2 pixels clock needed to capture one pixel */
		  (240 * 1) - 1  /* YSIZE DCMI Line number    : All 240 lines are captured */
  );
  HAL_DCMI_EnableCrop(&hdcmi);

  HAL_DMA2D_ConfigDeadTime(&hdma2d, 2);
  HAL_DMA2D_EnableDeadTime(&hdma2d);

  HAL_DCMI_Start_DMA(&hdcmi, DCMI_MODE_SNAPSHOT, buffaddr[dcmi_sw], CAPTURE_SIZE / 4);

  /* USER CODE END 2 */

  /* Infinite loop */
  /* USER CODE BEGIN WHILE */
  while (1)
  {
	printf("[FPS] DMA2D[%i]: %i | DCMI[%i]: %i\r\n", hdma2d.State, dma2d_fps, hdcmi.State, dcmi_fps);
	dma2d_fps = 0; dcmi_fps = 0;
	HAL_Delay(1000);

	// you gonk watchdog on dma transfers and restart dcmi if no update
	HAL_DCMI_Stop(&hdcmi);
	HAL_DCMI_Start_DMA(&hdcmi, DCMI_MODE_SNAPSHOT, buffaddr[dcmi_sw], CAPTURE_SIZE / 4);
    /* USER CODE END WHILE */

  }
}

void SystemClock_Config(void)
{
  RCC_OscInitTypeDef RCC_OscInitStruct = {0};
  RCC_ClkInitTypeDef RCC_ClkInitStruct = {0};
  RCC_PeriphCLKInitTypeDef PeriphClkInitStruct = {0};

  /** Configure LSE Drive Capability
  */
  HAL_PWR_EnableBkUpAccess();
  /** Configure the main internal regulator output voltage
  */
  __HAL_RCC_PWR_CLK_ENABLE();
  __HAL_PWR_VOLTAGESCALING_CONFIG(PWR_REGULATOR_VOLTAGE_SCALE1);
  /** Initializes the RCC Oscillators according to the specified parameters
  * in the RCC_OscInitTypeDef structure.
  */
  RCC_OscInitStruct.OscillatorType = RCC_OSCILLATORTYPE_HSE;
  RCC_OscInitStruct.HSEState = RCC_HSE_ON;
  RCC_OscInitStruct.PLL.PLLState = RCC_PLL_ON;
  RCC_OscInitStruct.PLL.PLLSource = RCC_PLLSOURCE_HSE;
  RCC_OscInitStruct.PLL.PLLM = 12;
  RCC_OscInitStruct.PLL.PLLN = 192;
  RCC_OscInitStruct.PLL.PLLP = RCC_PLLP_DIV2;
  RCC_OscInitStruct.PLL.PLLQ = 2;
  if (HAL_RCC_OscConfig(&RCC_OscInitStruct) != HAL_OK)
  {
    Error_Handler();
  }
  /** Activate the Over-Drive mode
  */
  if (HAL_PWREx_EnableOverDrive() != HAL_OK)
  {
    Error_Handler();
  }
  /** Initializes the CPU, AHB and APB buses clocks
  */
  RCC_ClkInitStruct.ClockType = RCC_CLOCKTYPE_HCLK|RCC_CLOCKTYPE_SYSCLK
                              |RCC_CLOCKTYPE_PCLK1|RCC_CLOCKTYPE_PCLK2;
  RCC_ClkInitStruct.SYSCLKSource = RCC_SYSCLKSOURCE_PLLCLK;
  RCC_ClkInitStruct.AHBCLKDivider = RCC_SYSCLK_DIV1;
  RCC_ClkInitStruct.APB1CLKDivider = RCC_HCLK_DIV4;
  RCC_ClkInitStruct.APB2CLKDivider = RCC_HCLK_DIV2;

  if (HAL_RCC_ClockConfig(&RCC_ClkInitStruct, FLASH_LATENCY_6) != HAL_OK)
  {
    Error_Handler();
  }
  PeriphClkInitStruct.PeriphClockSelection = RCC_PERIPHCLK_LTDC|RCC_PERIPHCLK_USART1
                              |RCC_PERIPHCLK_I2C1;
  PeriphClkInitStruct.PLLSAI.PLLSAIN = 50;
  PeriphClkInitStruct.PLLSAI.PLLSAIR = 2;
  PeriphClkInitStruct.PLLSAI.PLLSAIQ = 2;
  PeriphClkInitStruct.PLLSAI.PLLSAIP = RCC_PLLSAIP_DIV2;
  PeriphClkInitStruct.PLLSAIDivQ = 1;
  PeriphClkInitStruct.PLLSAIDivR = RCC_PLLSAIDIVR_2;
  PeriphClkInitStruct.Usart1ClockSelection = RCC_USART1CLKSOURCE_PCLK2;
  PeriphClkInitStruct.I2c1ClockSelection = RCC_I2C1CLKSOURCE_PCLK1;
  if (HAL_RCCEx_PeriphCLKConfig(&PeriphClkInitStruct) != HAL_OK)
  {
    Error_Handler();
  }
}

static void MX_DCMI_Init(void)
{

  hdcmi.Instance = DCMI;
  hdcmi.Init.SynchroMode = DCMI_SYNCHRO_HARDWARE;
  hdcmi.Init.PCKPolarity = DCMI_PCKPOLARITY_RISING;
  hdcmi.Init.VSPolarity = DCMI_VSPOLARITY_HIGH;
  hdcmi.Init.HSPolarity = DCMI_HSPOLARITY_LOW;
  hdcmi.Init.CaptureRate = DCMI_CR_ALL_FRAME;
  hdcmi.Init.ExtendedDataMode = DCMI_EXTEND_DATA_8B;
  hdcmi.Init.JPEGMode = DCMI_JPEG_DISABLE;
  hdcmi.Init.ByteSelectMode = DCMI_BSM_ALL;
  hdcmi.Init.ByteSelectStart = DCMI_OEBS_ODD;
  hdcmi.Init.LineSelectMode = DCMI_LSM_ALL;
  hdcmi.Init.LineSelectStart = DCMI_OELS_ODD;
  if (HAL_DCMI_Init(&hdcmi) != HAL_OK)
  {
    Error_Handler();
  }

}

static void MX_DMA2D_Init(void)
{

  hdma2d.Instance = DMA2D;
  hdma2d.Init.Mode = DMA2D_M2M;
  hdma2d.Init.ColorMode = DMA2D_OUTPUT_RGB565;
  hdma2d.Init.OutputOffset = 0;
  hdma2d.LayerCfg[1].InputOffset = 0;
  hdma2d.LayerCfg[1].InputColorMode = DMA2D_INPUT_RGB565;
  hdma2d.LayerCfg[1].AlphaMode = DMA2D_NO_MODIF_ALPHA;
  hdma2d.LayerCfg[1].InputAlpha = 0;
  if (HAL_DMA2D_Init(&hdma2d) != HAL_OK)
  {
    Error_Handler();
  }
  if (HAL_DMA2D_ConfigLayer(&hdma2d, 1) != HAL_OK)
  {
    Error_Handler();
  }

}

static void MX_I2C1_Init(void)
{

  hi2c1.Instance = I2C1;
  hi2c1.Init.Timing = 0x00C0EAFF;
  hi2c1.Init.OwnAddress1 = 0;
  hi2c1.Init.AddressingMode = I2C_ADDRESSINGMODE_7BIT;
  hi2c1.Init.DualAddressMode = I2C_DUALADDRESS_DISABLE;
  hi2c1.Init.OwnAddress2 = 0;
  hi2c1.Init.OwnAddress2Masks = I2C_OA2_NOMASK;
  hi2c1.Init.GeneralCallMode = I2C_GENERALCALL_DISABLE;
  hi2c1.Init.NoStretchMode = I2C_NOSTRETCH_DISABLE;
  if (HAL_I2C_Init(&hi2c1) != HAL_OK)
  {
    Error_Handler();
  }
  /** Configure Analogue filter
  */
  if (HAL_I2CEx_ConfigAnalogFilter(&hi2c1, I2C_ANALOGFILTER_ENABLE) != HAL_OK)
  {
    Error_Handler();
  }
  /** Configure Digital filter
  */
  if (HAL_I2CEx_ConfigDigitalFilter(&hi2c1, 0) != HAL_OK)
  {
    Error_Handler();
  }

}

static void MX_LTDC_Init(void)
{

  LTDC_LayerCfgTypeDef pLayerCfg = {0};

  hltdc.Instance = LTDC;
  hltdc.Init.HSPolarity = LTDC_HSPOLARITY_AL;
  hltdc.Init.VSPolarity = LTDC_VSPOLARITY_AL;
  hltdc.Init.DEPolarity = LTDC_DEPOLARITY_AL;
  hltdc.Init.PCPolarity = LTDC_PCPOLARITY_IPC;
  hltdc.Init.HorizontalSync = 40;
  hltdc.Init.VerticalSync = 9;
  hltdc.Init.AccumulatedHBP = 53;
  hltdc.Init.AccumulatedVBP = 11;
  hltdc.Init.AccumulatedActiveW = 533;
  hltdc.Init.AccumulatedActiveH = 283;
  hltdc.Init.TotalWidth = 565;
  hltdc.Init.TotalHeigh = 285;
  hltdc.Init.Backcolor.Blue = 0;
  hltdc.Init.Backcolor.Green = 0;
  hltdc.Init.Backcolor.Red = 0;
  if (HAL_LTDC_Init(&hltdc) != HAL_OK)
  {
    Error_Handler();
  }
  pLayerCfg.WindowX0 = 0;
  pLayerCfg.WindowX1 = 480;
  pLayerCfg.WindowY0 = 0;
  pLayerCfg.WindowY1 = 272;
  pLayerCfg.PixelFormat = LTDC_PIXEL_FORMAT_RGB565;
  pLayerCfg.Alpha = 255;
  pLayerCfg.Alpha0 = 0;
  pLayerCfg.BlendingFactor1 = LTDC_BLENDING_FACTOR1_PAxCA;
  pLayerCfg.BlendingFactor2 = LTDC_BLENDING_FACTOR2_PAxCA;
  pLayerCfg.FBStartAdress = 0xC0000000;
  pLayerCfg.ImageWidth = 480;
  pLayerCfg.ImageHeight = 272;
  pLayerCfg.Backcolor.Blue = 0;
  pLayerCfg.Backcolor.Green = 0;
  pLayerCfg.Backcolor.Red = 0;
  if (HAL_LTDC_ConfigLayer(&hltdc, &pLayerCfg, 0) != HAL_OK)
  {
    Error_Handler();
  }

}

static void MX_USART1_UART_Init(void)
{

  huart1.Instance = USART1;
  huart1.Init.BaudRate = 115200;
  huart1.Init.WordLength = UART_WORDLENGTH_8B;
  huart1.Init.StopBits = UART_STOPBITS_1;
  huart1.Init.Parity = UART_PARITY_NONE;
  huart1.Init.Mode = UART_MODE_TX_RX;
  huart1.Init.HwFlowCtl = UART_HWCONTROL_NONE;
  huart1.Init.OverSampling = UART_OVERSAMPLING_16;
  huart1.Init.OneBitSampling = UART_ONE_BIT_SAMPLE_DISABLE;
  huart1.AdvancedInit.AdvFeatureInit = UART_ADVFEATURE_NO_INIT;
  if (HAL_UART_Init(&huart1) != HAL_OK)
  {
    Error_Handler();
  }

}

static void MX_DMA_Init(void)
{

  /* DMA controller clock enable */
  __HAL_RCC_DMA2_CLK_ENABLE();

  /* DMA interrupt init */
  /* DMA2_Stream1_IRQn interrupt configuration */
  HAL_NVIC_SetPriority(DMA2_Stream1_IRQn, 0, 0);
  HAL_NVIC_EnableIRQ(DMA2_Stream1_IRQn);

}

/* FMC initialization function */
static void MX_FMC_Init(void)
{

  FMC_SDRAM_TimingTypeDef SdramTiming = {0};

  /** Perform the SDRAM1 memory initialization sequence
  */
  hsdram1.Instance = FMC_SDRAM_DEVICE;
  /* hsdram1.Init */
  hsdram1.Init.SDBank = FMC_SDRAM_BANK1;
  hsdram1.Init.ColumnBitsNumber = FMC_SDRAM_COLUMN_BITS_NUM_8;
  hsdram1.Init.RowBitsNumber = FMC_SDRAM_ROW_BITS_NUM_12;
  hsdram1.Init.MemoryDataWidth = FMC_SDRAM_MEM_BUS_WIDTH_16;
  hsdram1.Init.InternalBankNumber = FMC_SDRAM_INTERN_BANKS_NUM_4;
  hsdram1.Init.CASLatency = FMC_SDRAM_CAS_LATENCY_2;
  hsdram1.Init.WriteProtection = FMC_SDRAM_WRITE_PROTECTION_DISABLE;
  hsdram1.Init.SDClockPeriod = FMC_SDRAM_CLOCK_PERIOD_2;
  hsdram1.Init.ReadBurst = FMC_SDRAM_RBURST_ENABLE;
  hsdram1.Init.ReadPipeDelay = FMC_SDRAM_RPIPE_DELAY_0;
  /* SdramTiming */
  SdramTiming.LoadToActiveDelay = 2;
  SdramTiming.ExitSelfRefreshDelay = 7;
  SdramTiming.SelfRefreshTime = 4;
  SdramTiming.RowCycleDelay = 7;
  SdramTiming.WriteRecoveryTime = 3;
  SdramTiming.RPDelay = 2;
  SdramTiming.RCDDelay = 2;

  if (HAL_SDRAM_Init(&hsdram1, &SdramTiming) != HAL_OK)
  {
    Error_Handler( );
  }

}

static void MX_GPIO_Init(void)
{
  GPIO_InitTypeDef GPIO_InitStruct = {0};

  /* GPIO Ports Clock Enable */
  __HAL_RCC_GPIOE_CLK_ENABLE();
  __HAL_RCC_GPIOG_CLK_ENABLE();
  __HAL_RCC_GPIOB_CLK_ENABLE();
  __HAL_RCC_GPIOD_CLK_ENABLE();
  __HAL_RCC_GPIOC_CLK_ENABLE();
  __HAL_RCC_GPIOA_CLK_ENABLE();
  __HAL_RCC_GPIOJ_CLK_ENABLE();
  __HAL_RCC_GPIOI_CLK_ENABLE();
  __HAL_RCC_GPIOK_CLK_ENABLE();
  __HAL_RCC_GPIOF_CLK_ENABLE();
  __HAL_RCC_GPIOH_CLK_ENABLE();

  /*Configure GPIO pin Output Level */
  HAL_GPIO_WritePin(OTG_FS_PowerSwitchOn_GPIO_Port, OTG_FS_PowerSwitchOn_Pin, GPIO_PIN_SET);

  /*Configure GPIO pin Output Level */
  HAL_GPIO_WritePin(GPIOI, ARDUINO_D7_Pin|ARDUINO_D8_Pin, GPIO_PIN_RESET);

  /*Configure GPIO pin Output Level */
  HAL_GPIO_WritePin(LCD_BL_CTRL_GPIO_Port, LCD_BL_CTRL_Pin, GPIO_PIN_SET);

  /*Configure GPIO pin Output Level */
  HAL_GPIO_WritePin(LCD_DISP_GPIO_Port, LCD_DISP_Pin, GPIO_PIN_SET);

  /*Configure GPIO pin Output Level */
  HAL_GPIO_WritePin(DCMI_PWR_EN_GPIO_Port, DCMI_PWR_EN_Pin, GPIO_PIN_RESET);

  /*Configure GPIO pin Output Level */
  HAL_GPIO_WritePin(GPIOG, ARDUINO_D4_Pin|ARDUINO_D2_Pin|EXT_RST_Pin, GPIO_PIN_RESET);

  /*Configure GPIO pin : OTG_HS_OverCurrent_Pin */
  GPIO_InitStruct.Pin = OTG_HS_OverCurrent_Pin;
  GPIO_InitStruct.Mode = GPIO_MODE_INPUT;
  GPIO_InitStruct.Pull = GPIO_NOPULL;
  HAL_GPIO_Init(OTG_HS_OverCurrent_GPIO_Port, &GPIO_InitStruct);

  /*Configure GPIO pin : QSPI_D2_Pin */
  GPIO_InitStruct.Pin = QSPI_D2_Pin;
  GPIO_InitStruct.Mode = GPIO_MODE_AF_PP;
  GPIO_InitStruct.Pull = GPIO_NOPULL;
  GPIO_InitStruct.Speed = GPIO_SPEED_FREQ_VERY_HIGH;
  GPIO_InitStruct.Alternate = GPIO_AF9_QUADSPI;
  HAL_GPIO_Init(QSPI_D2_GPIO_Port, &GPIO_InitStruct);

  /*Configure GPIO pins : RMII_TXD1_Pin RMII_TXD0_Pin RMII_TX_EN_Pin */
  GPIO_InitStruct.Pin = RMII_TXD1_Pin|RMII_TXD0_Pin|RMII_TX_EN_Pin;
  GPIO_InitStruct.Mode = GPIO_MODE_AF_PP;
  GPIO_InitStruct.Pull = GPIO_NOPULL;
  GPIO_InitStruct.Speed = GPIO_SPEED_FREQ_VERY_HIGH;
  GPIO_InitStruct.Alternate = GPIO_AF11_ETH;
  HAL_GPIO_Init(GPIOG, &GPIO_InitStruct);

  /*Configure GPIO pins : ULPI_D7_Pin ULPI_D6_Pin ULPI_D5_Pin ULPI_D3_Pin
                           ULPI_D2_Pin ULPI_D1_Pin ULPI_D4_Pin */
  GPIO_InitStruct.Pin = ULPI_D7_Pin|ULPI_D6_Pin|ULPI_D5_Pin|ULPI_D3_Pin
                          |ULPI_D2_Pin|ULPI_D1_Pin|ULPI_D4_Pin;
  GPIO_InitStruct.Mode = GPIO_MODE_AF_PP;
  GPIO_InitStruct.Pull = GPIO_NOPULL;
  GPIO_InitStruct.Speed = GPIO_SPEED_FREQ_VERY_HIGH;
  GPIO_InitStruct.Alternate = GPIO_AF10_OTG_HS;
  HAL_GPIO_Init(GPIOB, &GPIO_InitStruct);

  /*Configure GPIO pin : ARDUINO_PWM_D3_Pin */
  GPIO_InitStruct.Pin = ARDUINO_PWM_D3_Pin;
  GPIO_InitStruct.Mode = GPIO_MODE_AF_PP;
  GPIO_InitStruct.Pull = GPIO_NOPULL;
  GPIO_InitStruct.Speed = GPIO_SPEED_FREQ_LOW;
  GPIO_InitStruct.Alternate = GPIO_AF2_TIM3;
  HAL_GPIO_Init(ARDUINO_PWM_D3_GPIO_Port, &GPIO_InitStruct);

  /*Configure GPIO pin : SPDIF_RX0_Pin */
  GPIO_InitStruct.Pin = SPDIF_RX0_Pin;
  GPIO_InitStruct.Mode = GPIO_MODE_AF_PP;
  GPIO_InitStruct.Pull = GPIO_NOPULL;
  GPIO_InitStruct.Speed = GPIO_SPEED_FREQ_LOW;
  GPIO_InitStruct.Alternate = GPIO_AF8_SPDIFRX;
  HAL_GPIO_Init(SPDIF_RX0_GPIO_Port, &GPIO_InitStruct);

  /*Configure GPIO pins : SDMMC_CK_Pin SDMMC_D3_Pin SDMMC_D2_Pin PC9
                           PC8 */
  GPIO_InitStruct.Pin = SDMMC_CK_Pin|SDMMC_D3_Pin|SDMMC_D2_Pin|GPIO_PIN_9
                          |GPIO_PIN_8;
  GPIO_InitStruct.Mode = GPIO_MODE_AF_PP;
  GPIO_InitStruct.Pull = GPIO_NOPULL;
  GPIO_InitStruct.Speed = GPIO_SPEED_FREQ_VERY_HIGH;
  GPIO_InitStruct.Alternate = GPIO_AF12_SDMMC1;
  HAL_GPIO_Init(GPIOC, &GPIO_InitStruct);

  /*Configure GPIO pin : ARDUINO_PWM_D9_Pin */
  GPIO_InitStruct.Pin = ARDUINO_PWM_D9_Pin;
  GPIO_InitStruct.Mode = GPIO_MODE_AF_PP;
  GPIO_InitStruct.Pull = GPIO_NOPULL;
  GPIO_InitStruct.Speed = GPIO_SPEED_FREQ_LOW;
  GPIO_InitStruct.Alternate = GPIO_AF1_TIM2;
  HAL_GPIO_Init(ARDUINO_PWM_D9_GPIO_Port, &GPIO_InitStruct);

  /*Configure GPIO pin : QSPI_NCS_Pin */
  GPIO_InitStruct.Pin = QSPI_NCS_Pin;
  GPIO_InitStruct.Mode = GPIO_MODE_AF_PP;
  GPIO_InitStruct.Pull = GPIO_NOPULL;
  GPIO_InitStruct.Speed = GPIO_SPEED_FREQ_VERY_HIGH;
  GPIO_InitStruct.Alternate = GPIO_AF10_QUADSPI;
  HAL_GPIO_Init(QSPI_NCS_GPIO_Port, &GPIO_InitStruct);

  /*Configure GPIO pin : OTG_FS_VBUS_Pin */
  GPIO_InitStruct.Pin = OTG_FS_VBUS_Pin;
  GPIO_InitStruct.Mode = GPIO_MODE_INPUT;
  GPIO_InitStruct.Pull = GPIO_NOPULL;
  HAL_GPIO_Init(OTG_FS_VBUS_GPIO_Port, &GPIO_InitStruct);

  /*Configure GPIO pin : Audio_INT_Pin */
  GPIO_InitStruct.Pin = Audio_INT_Pin;
  GPIO_InitStruct.Mode = GPIO_MODE_EVT_RISING;
  GPIO_InitStruct.Pull = GPIO_NOPULL;
  HAL_GPIO_Init(Audio_INT_GPIO_Port, &GPIO_InitStruct);

  /*Configure GPIO pins : OTG_FS_P_Pin OTG_FS_N_Pin OTG_FS_ID_Pin */
  GPIO_InitStruct.Pin = OTG_FS_P_Pin|OTG_FS_N_Pin|OTG_FS_ID_Pin;
  GPIO_InitStruct.Mode = GPIO_MODE_AF_PP;
  GPIO_InitStruct.Pull = GPIO_NOPULL;
  GPIO_InitStruct.Speed = GPIO_SPEED_FREQ_VERY_HIGH;
  GPIO_InitStruct.Alternate = GPIO_AF10_OTG_FS;
  HAL_GPIO_Init(GPIOA, &GPIO_InitStruct);

  /*Configure GPIO pins : SAI2_MCLKA_Pin SAI2_SCKA_Pin SAI2_FSA_Pin SAI2_SDA_Pin */
  GPIO_InitStruct.Pin = SAI2_MCLKA_Pin|SAI2_SCKA_Pin|SAI2_FSA_Pin|SAI2_SDA_Pin;
  GPIO_InitStruct.Mode = GPIO_MODE_AF_PP;
  GPIO_InitStruct.Pull = GPIO_NOPULL;
  GPIO_InitStruct.Speed = GPIO_SPEED_FREQ_LOW;
  GPIO_InitStruct.Alternate = GPIO_AF10_SAI2;
  HAL_GPIO_Init(GPIOI, &GPIO_InitStruct);

  /*Configure GPIO pin : SAI2_SDB_Pin */
  GPIO_InitStruct.Pin = SAI2_SDB_Pin;
  GPIO_InitStruct.Mode = GPIO_MODE_AF_PP;
  GPIO_InitStruct.Pull = GPIO_NOPULL;
  GPIO_InitStruct.Speed = GPIO_SPEED_FREQ_LOW;
  GPIO_InitStruct.Alternate = GPIO_AF10_SAI2;
  HAL_GPIO_Init(SAI2_SDB_GPIO_Port, &GPIO_InitStruct);

  /*Configure GPIO pin : OTG_FS_PowerSwitchOn_Pin */
  GPIO_InitStruct.Pin = OTG_FS_PowerSwitchOn_Pin;
  GPIO_InitStruct.Mode = GPIO_MODE_OUTPUT_PP;
  GPIO_InitStruct.Pull = GPIO_NOPULL;
  GPIO_InitStruct.Speed = GPIO_SPEED_FREQ_LOW;
  HAL_GPIO_Init(OTG_FS_PowerSwitchOn_GPIO_Port, &GPIO_InitStruct);

  /*Configure GPIO pins : ARDUINO_D7_Pin ARDUINO_D8_Pin LCD_DISP_Pin */
  GPIO_InitStruct.Pin = ARDUINO_D7_Pin|ARDUINO_D8_Pin|LCD_DISP_Pin;
  GPIO_InitStruct.Mode = GPIO_MODE_OUTPUT_PP;
  GPIO_InitStruct.Pull = GPIO_NOPULL;
  GPIO_InitStruct.Speed = GPIO_SPEED_FREQ_LOW;
  HAL_GPIO_Init(GPIOI, &GPIO_InitStruct);

  /*Configure GPIO pin : uSD_Detect_Pin */
  GPIO_InitStruct.Pin = uSD_Detect_Pin;
  GPIO_InitStruct.Mode = GPIO_MODE_INPUT;
  GPIO_InitStruct.Pull = GPIO_NOPULL;
  HAL_GPIO_Init(uSD_Detect_GPIO_Port, &GPIO_InitStruct);

  /*Configure GPIO pin : LCD_BL_CTRL_Pin */
  GPIO_InitStruct.Pin = LCD_BL_CTRL_Pin;
  GPIO_InitStruct.Mode = GPIO_MODE_OUTPUT_PP;
  GPIO_InitStruct.Pull = GPIO_NOPULL;
  GPIO_InitStruct.Speed = GPIO_SPEED_FREQ_LOW;
  HAL_GPIO_Init(LCD_BL_CTRL_GPIO_Port, &GPIO_InitStruct);

  /*Configure GPIO pin : OTG_FS_OverCurrent_Pin */
  GPIO_InitStruct.Pin = OTG_FS_OverCurrent_Pin;
  GPIO_InitStruct.Mode = GPIO_MODE_INPUT;
  GPIO_InitStruct.Pull = GPIO_NOPULL;
  HAL_GPIO_Init(OTG_FS_OverCurrent_GPIO_Port, &GPIO_InitStruct);

  /*Configure GPIO pin : SDMMC_D0_Pin */
  GPIO_InitStruct.Pin = SDMMC_D0_Pin;
  GPIO_InitStruct.Mode = GPIO_MODE_AF_PP;
  GPIO_InitStruct.Pull = GPIO_NOPULL;
  GPIO_InitStruct.Speed = GPIO_SPEED_FREQ_VERY_HIGH;
  GPIO_InitStruct.Alternate = GPIO_AF12_SDMMC1;
  HAL_GPIO_Init(SDMMC_D0_GPIO_Port, &GPIO_InitStruct);

  /*Configure GPIO pins : TP3_Pin NC2_Pin */
  GPIO_InitStruct.Pin = TP3_Pin|NC2_Pin;
  GPIO_InitStruct.Mode = GPIO_MODE_INPUT;
  GPIO_InitStruct.Pull = GPIO_NOPULL;
  HAL_GPIO_Init(GPIOH, &GPIO_InitStruct);

  /*Configure GPIO pin : ARDUINO_SCK_D13_Pin */
  GPIO_InitStruct.Pin = ARDUINO_SCK_D13_Pin;
  GPIO_InitStruct.Mode = GPIO_MODE_AF_PP;
  GPIO_InitStruct.Pull = GPIO_NOPULL;
  GPIO_InitStruct.Speed = GPIO_SPEED_FREQ_LOW;
  GPIO_InitStruct.Alternate = GPIO_AF5_SPI2;
  HAL_GPIO_Init(ARDUINO_SCK_D13_GPIO_Port, &GPIO_InitStruct);

  /*Configure GPIO pin : DCMI_PWR_EN_Pin */
  GPIO_InitStruct.Pin = DCMI_PWR_EN_Pin;
  GPIO_InitStruct.Mode = GPIO_MODE_OUTPUT_PP;
  GPIO_InitStruct.Pull = GPIO_NOPULL;
  GPIO_InitStruct.Speed = GPIO_SPEED_FREQ_LOW;
  HAL_GPIO_Init(DCMI_PWR_EN_GPIO_Port, &GPIO_InitStruct);

  /*Configure GPIO pin : ARDUINO_PWM_CS_D5_Pin */
  GPIO_InitStruct.Pin = ARDUINO_PWM_CS_D5_Pin;
  GPIO_InitStruct.Mode = GPIO_MODE_AF_PP;
  GPIO_InitStruct.Pull = GPIO_NOPULL;
  GPIO_InitStruct.Speed = GPIO_SPEED_FREQ_LOW;
  GPIO_InitStruct.Alternate = GPIO_AF2_TIM5;
  HAL_GPIO_Init(ARDUINO_PWM_CS_D5_GPIO_Port, &GPIO_InitStruct);

  /*Configure GPIO pin : ARDUINO_PWM_D10_Pin */
  GPIO_InitStruct.Pin = ARDUINO_PWM_D10_Pin;
  GPIO_InitStruct.Mode = GPIO_MODE_AF_PP;
  GPIO_InitStruct.Pull = GPIO_NOPULL;
  GPIO_InitStruct.Speed = GPIO_SPEED_FREQ_LOW;
  GPIO_InitStruct.Alternate = GPIO_AF1_TIM1;
  HAL_GPIO_Init(ARDUINO_PWM_D10_GPIO_Port, &GPIO_InitStruct);

  /*Configure GPIO pin : LCD_INT_Pin */
  GPIO_InitStruct.Pin = LCD_INT_Pin;
  GPIO_InitStruct.Mode = GPIO_MODE_EVT_RISING;
  GPIO_InitStruct.Pull = GPIO_NOPULL;
  HAL_GPIO_Init(LCD_INT_GPIO_Port, &GPIO_InitStruct);

  /*Configure GPIO pins : ARDUINO_RX_D0_Pin ARDUINO_TX_D1_Pin */
  GPIO_InitStruct.Pin = ARDUINO_RX_D0_Pin|ARDUINO_TX_D1_Pin;
  GPIO_InitStruct.Mode = GPIO_MODE_AF_PP;
  GPIO_InitStruct.Pull = GPIO_NOPULL;
  GPIO_InitStruct.Speed = GPIO_SPEED_FREQ_VERY_HIGH;
  GPIO_InitStruct.Alternate = GPIO_AF8_USART6;
  HAL_GPIO_Init(GPIOC, &GPIO_InitStruct);

  /*Configure GPIO pin : ULPI_NXT_Pin */
  GPIO_InitStruct.Pin = ULPI_NXT_Pin;
  GPIO_InitStruct.Mode = GPIO_MODE_AF_PP;
  GPIO_InitStruct.Pull = GPIO_NOPULL;
  GPIO_InitStruct.Speed = GPIO_SPEED_FREQ_VERY_HIGH;
  GPIO_InitStruct.Alternate = GPIO_AF10_OTG_HS;
  HAL_GPIO_Init(ULPI_NXT_GPIO_Port, &GPIO_InitStruct);

  /*Configure GPIO pins : ARDUINO_D4_Pin ARDUINO_D2_Pin EXT_RST_Pin */
  GPIO_InitStruct.Pin = ARDUINO_D4_Pin|ARDUINO_D2_Pin|EXT_RST_Pin;
  GPIO_InitStruct.Mode = GPIO_MODE_OUTPUT_PP;
  GPIO_InitStruct.Pull = GPIO_NOPULL;
  GPIO_InitStruct.Speed = GPIO_SPEED_FREQ_LOW;
  HAL_GPIO_Init(GPIOG, &GPIO_InitStruct);

  /*Configure GPIO pins : ARDUINO_A4_Pin ARDUINO_A5_Pin ARDUINO_A1_Pin ARDUINO_A2_Pin
                           ARDUINO_A3_Pin */
  GPIO_InitStruct.Pin = ARDUINO_A4_Pin|ARDUINO_A5_Pin|ARDUINO_A1_Pin|ARDUINO_A2_Pin
                          |ARDUINO_A3_Pin;
  GPIO_InitStruct.Mode = GPIO_MODE_ANALOG;
  GPIO_InitStruct.Pull = GPIO_NOPULL;
  HAL_GPIO_Init(GPIOF, &GPIO_InitStruct);

  /*Configure GPIO pins : ULPI_STP_Pin ULPI_DIR_Pin */
  GPIO_InitStruct.Pin = ULPI_STP_Pin|ULPI_DIR_Pin;
  GPIO_InitStruct.Mode = GPIO_MODE_AF_PP;
  GPIO_InitStruct.Pull = GPIO_NOPULL;
  GPIO_InitStruct.Speed = GPIO_SPEED_FREQ_VERY_HIGH;
  GPIO_InitStruct.Alternate = GPIO_AF10_OTG_HS;
  HAL_GPIO_Init(GPIOC, &GPIO_InitStruct);

  /*Configure GPIO pins : RMII_MDC_Pin RMII_RXD0_Pin RMII_RXD1_Pin */
  GPIO_InitStruct.Pin = RMII_MDC_Pin|RMII_RXD0_Pin|RMII_RXD1_Pin;
  GPIO_InitStruct.Mode = GPIO_MODE_AF_PP;
  GPIO_InitStruct.Pull = GPIO_NOPULL;
  GPIO_InitStruct.Speed = GPIO_SPEED_FREQ_VERY_HIGH;
  GPIO_InitStruct.Alternate = GPIO_AF11_ETH;
  HAL_GPIO_Init(GPIOC, &GPIO_InitStruct);

  /*Configure GPIO pin : PB2 */
  GPIO_InitStruct.Pin = GPIO_PIN_2;
  GPIO_InitStruct.Mode = GPIO_MODE_AF_PP;
  GPIO_InitStruct.Pull = GPIO_NOPULL;
  GPIO_InitStruct.Speed = GPIO_SPEED_FREQ_VERY_HIGH;
  GPIO_InitStruct.Alternate = GPIO_AF9_QUADSPI;
  HAL_GPIO_Init(GPIOB, &GPIO_InitStruct);

  /*Configure GPIO pins : QSPI_D1_Pin QSPI_D3_Pin QSPI_D0_Pin */
  GPIO_InitStruct.Pin = QSPI_D1_Pin|QSPI_D3_Pin|QSPI_D0_Pin;
  GPIO_InitStruct.Mode = GPIO_MODE_AF_PP;
  GPIO_InitStruct.Pull = GPIO_NOPULL;
  GPIO_InitStruct.Speed = GPIO_SPEED_FREQ_VERY_HIGH;
  GPIO_InitStruct.Alternate = GPIO_AF9_QUADSPI;
  HAL_GPIO_Init(GPIOD, &GPIO_InitStruct);

  /*Configure GPIO pin : RMII_RXER_Pin */
  GPIO_InitStruct.Pin = RMII_RXER_Pin;
  GPIO_InitStruct.Mode = GPIO_MODE_INPUT;
  GPIO_InitStruct.Pull = GPIO_NOPULL;
  HAL_GPIO_Init(RMII_RXER_GPIO_Port, &GPIO_InitStruct);

  /*Configure GPIO pins : RMII_REF_CLK_Pin RMII_MDIO_Pin RMII_CRS_DV_Pin */
  GPIO_InitStruct.Pin = RMII_REF_CLK_Pin|RMII_MDIO_Pin|RMII_CRS_DV_Pin;
  GPIO_InitStruct.Mode = GPIO_MODE_AF_PP;
  GPIO_InitStruct.Pull = GPIO_NOPULL;
  GPIO_InitStruct.Speed = GPIO_SPEED_FREQ_VERY_HIGH;
  GPIO_InitStruct.Alternate = GPIO_AF11_ETH;
  HAL_GPIO_Init(GPIOA, &GPIO_InitStruct);

  /*Configure GPIO pin : ARDUINO_A0_Pin */
  GPIO_InitStruct.Pin = ARDUINO_A0_Pin;
  GPIO_InitStruct.Mode = GPIO_MODE_ANALOG;
  GPIO_InitStruct.Pull = GPIO_NOPULL;
  HAL_GPIO_Init(ARDUINO_A0_GPIO_Port, &GPIO_InitStruct);

  /*Configure GPIO pins : LCD_SCL_Pin LCD_SDA_Pin */
  GPIO_InitStruct.Pin = LCD_SCL_Pin|LCD_SDA_Pin;
  GPIO_InitStruct.Mode = GPIO_MODE_AF_OD;
  GPIO_InitStruct.Pull = GPIO_PULLUP;
  GPIO_InitStruct.Speed = GPIO_SPEED_FREQ_VERY_HIGH;
  GPIO_InitStruct.Alternate = GPIO_AF4_I2C3;
  HAL_GPIO_Init(GPIOH, &GPIO_InitStruct);

  /*Configure GPIO pins : ULPI_CLK_Pin ULPI_D0_Pin */
  GPIO_InitStruct.Pin = ULPI_CLK_Pin|ULPI_D0_Pin;
  GPIO_InitStruct.Mode = GPIO_MODE_AF_PP;
  GPIO_InitStruct.Pull = GPIO_NOPULL;
  GPIO_InitStruct.Speed = GPIO_SPEED_FREQ_VERY_HIGH;
  GPIO_InitStruct.Alternate = GPIO_AF10_OTG_HS;
  HAL_GPIO_Init(GPIOA, &GPIO_InitStruct);

  /*Configure GPIO pin : ARDUINO_PWM_D6_Pin */
  GPIO_InitStruct.Pin = ARDUINO_PWM_D6_Pin;
  GPIO_InitStruct.Mode = GPIO_MODE_AF_PP;
  GPIO_InitStruct.Pull = GPIO_NOPULL;
  GPIO_InitStruct.Speed = GPIO_SPEED_FREQ_LOW;
  GPIO_InitStruct.Alternate = GPIO_AF9_TIM12;
  HAL_GPIO_Init(ARDUINO_PWM_D6_GPIO_Port, &GPIO_InitStruct);

  /*Configure GPIO pins : ARDUINO_MISO_D12_Pin ARDUINO_MOSI_PWM_D11_Pin */
  GPIO_InitStruct.Pin = ARDUINO_MISO_D12_Pin|ARDUINO_MOSI_PWM_D11_Pin;
  GPIO_InitStruct.Mode = GPIO_MODE_AF_PP;
  GPIO_InitStruct.Pull = GPIO_NOPULL;
  GPIO_InitStruct.Speed = GPIO_SPEED_FREQ_LOW;
  GPIO_InitStruct.Alternate = GPIO_AF5_SPI2;
  HAL_GPIO_Init(GPIOB, &GPIO_InitStruct);

}

void Error_Handler(void)
{
  __disable_irq();
  while (1)
  {
  }
}

/************************ (C) COPYRIGHT STMicroelectronics *****END OF FILE****/
